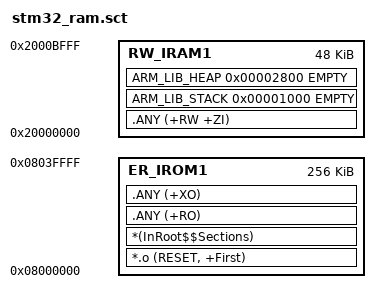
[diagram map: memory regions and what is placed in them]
; *************************************************************
; *** Scatter-Loading Description File generated by uVision ***
; *************************************************************

LR_IROM1 0x08000000 0x00040000  {    ; Load Region，起始地址 0x08000000，大小 256KB (0x40000)
  ER_IROM1 0x08000000 0x00040000  {  ; Execution Region，与 Load 区域一致
   *.o (RESET, +First)               ; 放入 reset 启动代码
   *(InRoot$$Sections)               ; 其他重要节
   .ANY (+RO)                        ; 所有只读段，包括 const 和代码
   .ANY (+XO)                        ; 执行段（可选）
  }
  RW_IRAM1 0x20000000 0x0000C000  {  ; RW/ZI 区，起始地址 0x20000000，大小 48KB
   .ANY (+RW +ZI)                    ; 可读写和零初始化段

   ARM_LIB_STACK 0x00001000 EMPTY    ; 4KB 栈
   ARM_LIB_HEAP  0x00002800 EMPTY    ; 10KB 堆，与FreeRTOS配置匹配
  }
}

